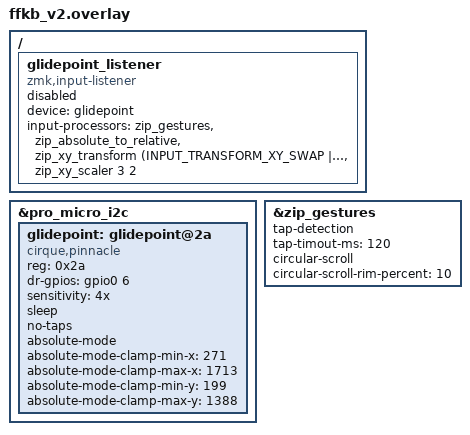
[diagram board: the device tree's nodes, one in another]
#include <input/processors.dtsi>
#include <dt-bindings/zmk/input_transform.h>
#include <behaviors/input_processor_gestures.dtsi>
#include <behaviors/input_processor_absolute_to_relative.dtsi>


&pro_micro_i2c {
    status = "okay";

    glidepoint: glidepoint@2a {
        compatible = "cirque,pinnacle";
        reg = <0x2a>;
        status = "okay";
        dr-gpios = <&gpio0 6 (GPIO_ACTIVE_HIGH)>;

        sensitivity = "4x";
        sleep;
        no-taps;
        absolute-mode;

        absolute-mode-clamp-min-x=<271>;
        absolute-mode-clamp-max-x=<1713>;
        absolute-mode-clamp-min-y=<199>;
        absolute-mode-clamp-max-y=<1388>;
    };

};

&zip_gestures {
    tap-detection;
    tap-timout-ms=<120>;
    circular-scroll;
    circular-scroll-rim-percent=<10>;
};

/ {
    glidepoint_listener: glidepoint_listener {
        compatible = "zmk,input-listener";
        status = "disabled";
        device = <&glidepoint>;
        input-processors = <
            &zip_gestures
            &zip_absolute_to_relative

            &zip_xy_transform (INPUT_TRANSFORM_XY_SWAP | INPUT_TRANSFORM_Y_INVERT)
            &zip_xy_scaler 3 2
        >;
    };
};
